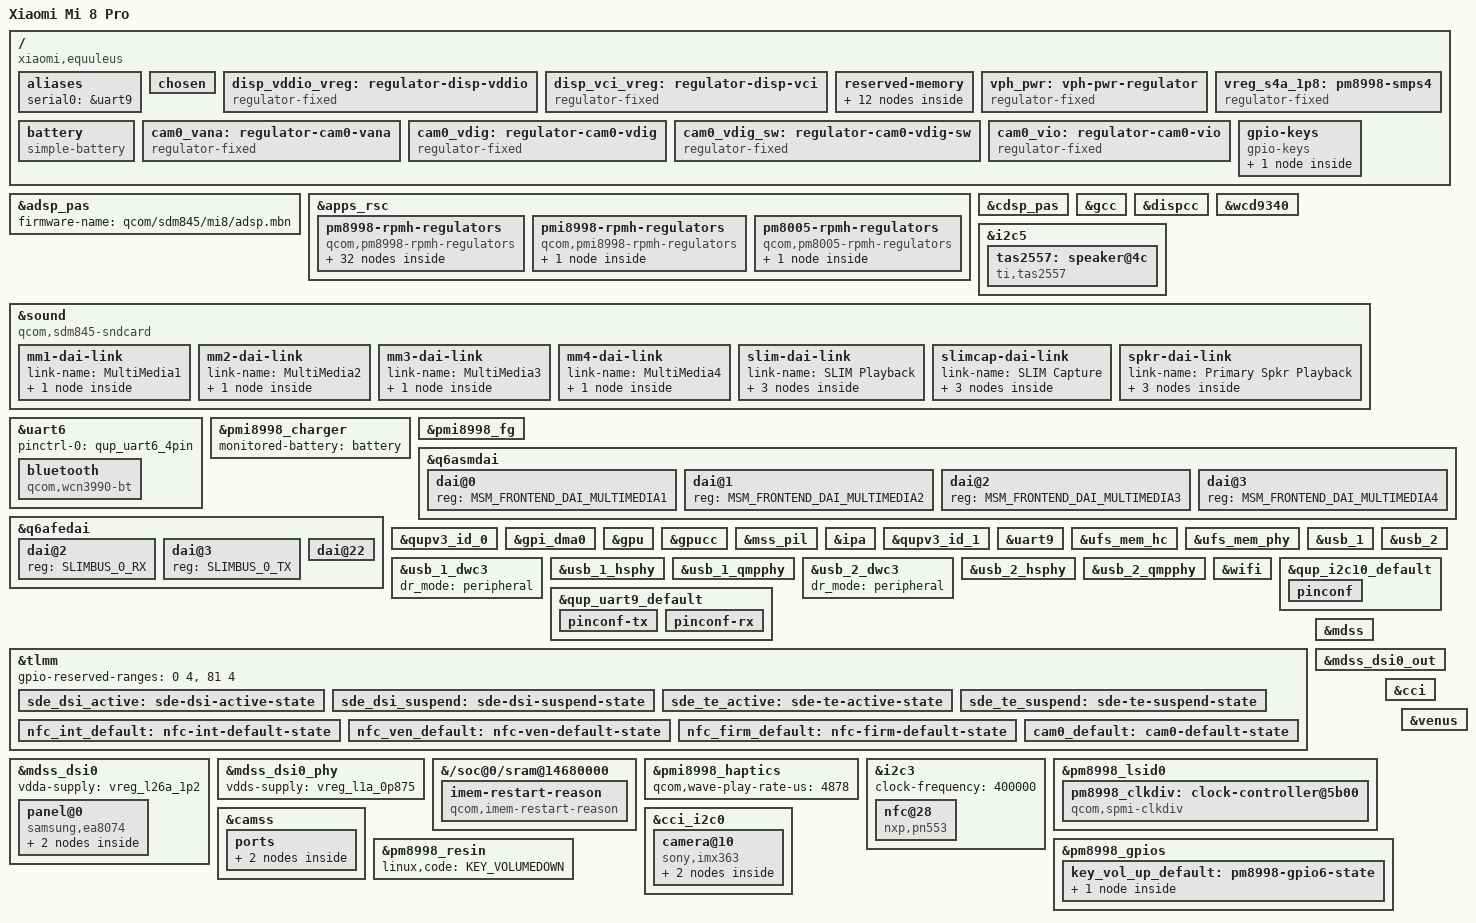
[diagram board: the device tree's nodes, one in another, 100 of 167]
// SPDX-License-Identifier: GPL-2.0
/*
 * SDM845 Xiaomi Mi 8 Pro (equuleus) device tree
 *
 * Copyright (c) 2021, The Linux Foundation. All rights reserved.
 */

/dts-v1/;

#include <dt-bindings/clock/qcom,camcc-sdm845.h>
#include <dt-bindings/gpio/gpio.h>
#include <dt-bindings/input/linux-event-codes.h>
#include <dt-bindings/pinctrl/qcom,pmic-gpio.h>
#include <dt-bindings/regulator/qcom,rpmh-regulator.h>
#include <dt-bindings/spmi/spmi.h>
#include <dt-bindings/sound/qcom,q6afe.h>
#include <dt-bindings/sound/qcom,q6asm.h>
#include <dt-bindings/sound/qcom,wcd934x.h>
#include "sdm845.dtsi"
/*
 * The WCD9340 codec on SLIMbus, shared by several sdm845 boards. It also
 * carries the interrupt pinctrl that the codec node references.
 */
#include "sdm845-wcd9340.dtsi"
/*
 * Brings in the PM8998 SPMI PMIC. Its PON block is what makes
 * "reboot bootloader" work: qcom-pon writes the reboot reason into the PMIC
 * scratch register and the bootloader reads it on the next boot to decide
 * between normal boot and fastboot. Without this include there is no pon@800
 * node at all, so qcom-pon binds to nothing and the reboot reason is lost.
 *
 * The file carries no regulators - those come from RPMh - so it does not
 * conflict with pm8998-rpmh-regulators.
 */
#include "pm8998.dtsi"
/*
 * The PMI8998 PMIC carries the charger and the fuel gauge. Board DTSes have to
 * include this themselves; nothing pulls it in automatically.
 */
#include "pmi8998.dtsi"

/*
 * Delete following upstream (sdm845.dtsi) reserved
 * memory mappings which are different in this device.
 */
/delete-node/ &tz_mem;
/delete-node/ &adsp_mem;
/delete-node/ &wlan_msa_mem;
/delete-node/ &mpss_region;
/delete-node/ &venus_mem;
/delete-node/ &cdsp_mem;
/delete-node/ &mba_region;
/delete-node/ &slpi_mem;
/delete-node/ &spss_mem;
/delete-node/ &rmtfs_mem;

/ {
	model = "Xiaomi Mi 8 Pro";
	compatible = "xiaomi,equuleus", "qcom,sdm845", "qcom,mtp";
	qcom,msm-id = <321 0x20001>;
	qcom,board-id = <79 0>;

	aliases {
		serial0 = &uart9;
	};

	chosen {
		#address-cells = <2>;
		#size-cells = <2>;
		ranges;


	};

	/*
	 * Panel rails. The downstream device tree switches both from tlmm gpios
	 * and expects them on at boot.
	 */
	disp_vddio_vreg: regulator-disp-vddio {
		compatible = "regulator-fixed";
		regulator-name = "disp_vddio";
		regulator-min-microvolt = <1800000>;
		regulator-max-microvolt = <1800000>;
		gpio = <&tlmm 23 GPIO_ACTIVE_HIGH>;
		enable-active-high;
		startup-delay-us = <4000>;
		regulator-boot-on;
	};

	disp_vci_vreg: regulator-disp-vci {
		compatible = "regulator-fixed";
		regulator-name = "disp_vci";
		regulator-min-microvolt = <3000000>;
		regulator-max-microvolt = <3000000>;
		gpio = <&tlmm 35 GPIO_ACTIVE_HIGH>;
		enable-active-high;
		startup-delay-us = <4000>;
		regulator-boot-on;
	};

	reserved-memory {

		/*
		 * pstore/ramoops: keep the last kernel messages in RAM across a
		 * reboot. Without this a panic leaves nothing behind - the console
		 * gadget only exists once the initramfs has started, so an early
		 * hang produces no output at all.
		 *
		 * Placed right after the framebuffer region (9d400000+02400000) and
		 * clear of everything sdm845.dtsi reserves below that.
		 */
		ramoops_region: ramoops@9f800000 {
			compatible = "ramoops";
			reg = <0x0 0x9f800000 0x0 0x100000>;
			record-size = <0x20000>;
			console-size = <0x40000>;
			ftrace-size = <0x0>;
			pmsg-size = <0x20000>;
		};

		/* hack: Framebuffer memory region. */
		framebuffer_region@9d400000 {
			reg = <0x0 0x9d400000 0x0 0x02400000>;
			no-map;
		};

		/* Reserved memory changes from downstream */
		adsp_mem: memory@8c500000 {
			reg = <0 0x8c500000 0 0x1e00000>;
			no-map;
		};

		wlan_msa_mem: memory@8e300000 {
			reg = <0 0x8e300000 0 0x100000>;
			no-map;
		};

		mpss_region: memory@8e400000 {
			reg = <0 0x8e400000 0 0x7800000>;
			no-map;
		};

		venus_mem: memory@95c00000 {
			reg = <0 0x95c00000 0 0x500000>;
			no-map;
		};

		cdsp_mem: memory@96100000 {
			reg = <0 0x96100000 0 0x800000>;
			no-map;
		};

		mba_region: memory@96900000 {
			reg = <0 0x96900000 0 0x200000>;
			no-map;
		};

		slpi_mem: memory@96b00000 {
			reg = <0 0x96b00000 0 0x1400000>;
			no-map;
		};

		spss_mem: memory@97f00000 {
			reg = <0 0x97f00000 0 0x100000>;
			no-map;
		};

		/*
		 * The rmtfs memory region in downstream is 'dynamically allocated'
		 * but given the same address every time. Hard code it as this address is
		 * where the modem firmware expects it to be.
		 */
		rmtfs_mem: memory@f7301000 {
			compatible = "qcom,rmtfs-mem";
			reg = <0 0xf7301000 0 0x200000>;
			no-map;

			qcom,client-id = <1>;
			qcom,vmid = <15>;
		};
		
		/*
		 * It seems like reserving the old rmtfs_mem region is also needed to prevent
		 * random crashes which are most likely modem related, more testing needed.
		 */
		removed_region: memory@88f00000 {
			no-map;
			reg = <0 0x88f00000 0 0x200000>;
		};
	};

	vph_pwr: vph-pwr-regulator {
		compatible = "regulator-fixed";
		regulator-name = "vph_pwr";
		regulator-min-microvolt = <3700000>;
		regulator-max-microvolt = <3700000>;
	};

	/*
	 * Apparently RPMh does not provide support for PM8998 S4 because it
	 * is always-on; model it as a fixed regulator.
	 */
	vreg_s4a_1p8: pm8998-smps4 {
		compatible = "regulator-fixed";
		regulator-name = "vreg_s4a_1p8";

		regulator-min-microvolt = <1800000>;
		regulator-max-microvolt = <1800000>;

		regulator-always-on;
		regulator-boot-on;

		vin-supply = <&vph_pwr>;
	};
};

&adsp_pas {
	status = "okay";
	firmware-name = "qcom/sdm845/mi8/adsp.mbn";
};

&apps_rsc {
	pm8998-rpmh-regulators {
		compatible = "qcom,pm8998-rpmh-regulators";
		qcom,pmic-id = "a";

		vdd-s1-supply = <&vph_pwr>;
		vdd-s2-supply = <&vph_pwr>;
		vdd-s3-supply = <&vph_pwr>;
		vdd-s4-supply = <&vph_pwr>;
		vdd-s5-supply = <&vph_pwr>;
		vdd-s6-supply = <&vph_pwr>;
		vdd-s7-supply = <&vph_pwr>;
		vdd-s8-supply = <&vph_pwr>;
		vdd-s9-supply = <&vph_pwr>;
		vdd-s10-supply = <&vph_pwr>;
		vdd-s11-supply = <&vph_pwr>;
		vdd-s12-supply = <&vph_pwr>;
		vdd-s13-supply = <&vph_pwr>;
		vdd-l1-l27-supply = <&vreg_s7a_1p025>;
		vdd-l2-l8-l17-supply = <&vreg_s3a_1p35>;
		vdd-l3-l11-supply = <&vreg_s7a_1p025>;
		vdd-l4-l5-supply = <&vreg_s7a_1p025>;
		vdd-l6-supply = <&vph_pwr>;
		vdd-l7-l12-l14-l15-supply = <&vreg_s5a_2p04>;
		vdd-l9-supply = <&vreg_bob>;
		vdd-l10-l23-l25-supply = <&vreg_bob>;
		vdd-l13-l19-l21-supply = <&vreg_bob>;
		vdd-l16-l28-supply = <&vreg_bob>;
		vdd-l18-l22-supply = <&vreg_bob>;
		vdd-l20-l24-supply = <&vreg_bob>;
		vdd-l26-supply = <&vreg_s3a_1p35>;
		vin-lvs-1-2-supply = <&vreg_s4a_1p8>;

		vreg_s2a_1p125: smps2 {
			regulator-min-microvolt = <1100000>;
			regulator-max-microvolt = <1100000>;
		};

		vreg_s3a_1p35: smps3 {
			regulator-min-microvolt = <1352000>;
			regulator-max-microvolt = <1352000>;
		};

		vreg_s5a_2p04: smps5 {
			regulator-min-microvolt = <1904000>;
			regulator-max-microvolt = <2040000>;
		};

		vreg_s7a_1p025: smps7 {
			regulator-min-microvolt = <900000>;
			regulator-max-microvolt = <1028000>;
		};

		vdd_qusb_hs0:
		vdda_hp_pcie_core:
		vdda_mipi_csi0_0p9:
		vdda_mipi_csi1_0p9:
		vdda_mipi_csi2_0p9:
		vdda_mipi_dsi0_pll:
		vdda_mipi_dsi1_pll:
		vdda_qlink_lv:
		vdda_qlink_lv_ck:
		vdda_qrefs_0p875:
		vdda_pcie_core:
		vdda_pll_cc_ebi01:
		vdda_pll_cc_ebi23:
		vdda_sp_sensor:
		vdda_ufs1_core:
		vdda_ufs2_core:
		vdda_usb1_ss_core:
		vdda_usb2_ss_core:
		vreg_l1a_0p875: ldo1 {
			regulator-min-microvolt = <880000>;
			regulator-max-microvolt = <880000>;
			regulator-initial-mode = <RPMH_REGULATOR_MODE_HPM>;
		};

		vddpx_10:
		vreg_l2a_1p2: ldo2 {
			regulator-min-microvolt = <1200000>;
			regulator-max-microvolt = <1200000>;
			regulator-initial-mode = <RPMH_REGULATOR_MODE_HPM>;
			regulator-always-on;
		};

		vreg_l3a_1p0: ldo3 {
			regulator-min-microvolt = <1000000>;
			regulator-max-microvolt = <1000000>;
			regulator-initial-mode = <RPMH_REGULATOR_MODE_HPM>;
		};

		vdd_wcss_cx:
		vdd_wcss_mx:
		vdda_wcss_pll:
		vreg_l5a_0p8: ldo5 {
			regulator-min-microvolt = <800000>;
			regulator-max-microvolt = <800000>;
			regulator-initial-mode = <RPMH_REGULATOR_MODE_HPM>;
		};

		vddpx_13:
		vreg_l6a_1p8: ldo6 {
			regulator-min-microvolt = <1856000>;
			regulator-max-microvolt = <1856000>;
			regulator-initial-mode = <RPMH_REGULATOR_MODE_HPM>;
		};

		vreg_l7a_1p8: ldo7 {
			regulator-min-microvolt = <1800000>;
			regulator-max-microvolt = <1800000>;
			regulator-initial-mode = <RPMH_REGULATOR_MODE_HPM>;
		};

		vreg_l8a_1p2: ldo8 {
			regulator-min-microvolt = <1200000>;
			regulator-max-microvolt = <1248000>;
			regulator-initial-mode = <RPMH_REGULATOR_MODE_HPM>;
		};

		vreg_l9a_1p8: ldo9 {
			regulator-min-microvolt = <1704000>;
			regulator-max-microvolt = <2928000>;
			regulator-initial-mode = <RPMH_REGULATOR_MODE_HPM>;
		};

		vreg_l10a_1p8: ldo10 {
			regulator-min-microvolt = <1704000>;
			regulator-max-microvolt = <2928000>;
			regulator-initial-mode = <RPMH_REGULATOR_MODE_HPM>;
		};

		vreg_l11a_1p0: ldo11 {
			regulator-min-microvolt = <1000000>;
			regulator-max-microvolt = <1048000>;
			regulator-initial-mode = <RPMH_REGULATOR_MODE_HPM>;
		};

		vdd_qfprom:
		vdd_qfprom_sp:
		vdda_apc1_cs_1p8:
		vdda_gfx_cs_1p8:
		vdda_qrefs_1p8:
		vdda_qusb_hs0_1p8:
		vddpx_11:
		vreg_l12a_1p8: ldo12 {
			regulator-min-microvolt = <1800000>;
			regulator-max-microvolt = <1800000>;
			regulator-initial-mode = <RPMH_REGULATOR_MODE_HPM>;
		};

		vddpx_2:
		vreg_l13a_2p95: ldo13 {
			regulator-min-microvolt = <1800000>;
			regulator-max-microvolt = <2960000>;
			regulator-initial-mode = <RPMH_REGULATOR_MODE_HPM>;
		};

		vreg_l14a_1p88: ldo14 {
			regulator-min-microvolt = <1800000>;
			regulator-max-microvolt = <1800000>;
			regulator-initial-mode = <RPMH_REGULATOR_MODE_HPM>;
		};

		vreg_l15a_1p8: ldo15 {
			regulator-min-microvolt = <1800000>;
			regulator-max-microvolt = <1800000>;
			regulator-initial-mode = <RPMH_REGULATOR_MODE_HPM>;
		};

		vreg_l16a_2p7: ldo16 {
			regulator-min-microvolt = <2704000>;
			regulator-max-microvolt = <2704000>;
			regulator-initial-mode = <RPMH_REGULATOR_MODE_HPM>;
		};

		vreg_l17a_1p3: ldo17 {
			regulator-min-microvolt = <1304000>;
			regulator-max-microvolt = <1304000>;
			regulator-initial-mode = <RPMH_REGULATOR_MODE_HPM>;
		};

		vreg_l18a_2p7: ldo18 {
			regulator-min-microvolt = <2704000>;
			regulator-max-microvolt = <2960000>;
			regulator-initial-mode = <RPMH_REGULATOR_MODE_HPM>;
		};

		vreg_l19a_3p0: ldo19 {
			regulator-min-microvolt = <2856000>;
			regulator-max-microvolt = <3104000>;
			regulator-initial-mode = <RPMH_REGULATOR_MODE_HPM>;
		};

		vreg_l20a_2p95: ldo20 {
			regulator-min-microvolt = <2704000>;
			regulator-max-microvolt = <2960000>;
			regulator-initial-mode = <RPMH_REGULATOR_MODE_HPM>;
		};

		vreg_l21a_2p95: ldo21 {
			regulator-min-microvolt = <2704000>;
			regulator-max-microvolt = <2960000>;
			regulator-initial-mode = <RPMH_REGULATOR_MODE_HPM>;
		};

		vreg_l22a_2p85: ldo22 {
			regulator-min-microvolt = <2864000>;
			regulator-max-microvolt = <3312000>;
			regulator-initial-mode = <RPMH_REGULATOR_MODE_HPM>;
		};

		vreg_l23a_3p3: ldo23 {
			regulator-min-microvolt = <3000000>;
			regulator-max-microvolt = <3312000>;
			regulator-initial-mode = <RPMH_REGULATOR_MODE_HPM>;
		};

		vdda_qusb_hs0_3p1:
		vreg_l24a_3p075: ldo24 {
			regulator-min-microvolt = <3088000>;
			regulator-max-microvolt = <3088000>;
			regulator-initial-mode = <RPMH_REGULATOR_MODE_HPM>;
		};

		vreg_l25a_3p3: ldo25 {
			regulator-min-microvolt = <3300000>;
			regulator-max-microvolt = <3312000>;
			regulator-initial-mode = <RPMH_REGULATOR_MODE_HPM>;
		};

		vdda_hp_pcie_1p2:
		vdda_hv_ebi0:
		vdda_hv_ebi1:
		vdda_hv_ebi2:
		vdda_hv_ebi3:
		vdda_mipi_csi_1p25:
		vdda_mipi_dsi0_1p2:
		vdda_mipi_dsi1_1p2:
		vdda_pcie_1p2:
		vdda_ufs1_1p2:
		vdda_ufs2_1p2:
		vdda_usb1_ss_1p2:
		vdda_usb2_ss_1p2:
		vreg_l26a_1p2: ldo26 {
			regulator-min-microvolt = <1200000>;
			regulator-max-microvolt = <1200000>;
			regulator-initial-mode = <RPMH_REGULATOR_MODE_HPM>;
		};

		vreg_l28a_3p0: ldo28 {
			regulator-min-microvolt = <2856000>;
			regulator-max-microvolt = <3008000>;
			regulator-initial-mode = <RPMH_REGULATOR_MODE_HPM>;
		};

		vreg_lvs1a_1p8: lvs1 {
			regulator-min-microvolt = <1800000>;
			regulator-max-microvolt = <1800000>;
		};

		vreg_lvs2a_1p8: lvs2 {
			regulator-min-microvolt = <1800000>;
			regulator-max-microvolt = <1800000>;
		};
	};

	pmi8998-rpmh-regulators {
		compatible = "qcom,pmi8998-rpmh-regulators";
		qcom,pmic-id = "b";

		vdd-bob-supply = <&vph_pwr>;

		vreg_bob: bob {
			regulator-min-microvolt = <3312000>;
			regulator-max-microvolt = <3600000>;
			regulator-initial-mode = <RPMH_REGULATOR_MODE_AUTO>;
			regulator-allow-bypass;
		};
	};

	pm8005-rpmh-regulators {
		compatible = "qcom,pm8005-rpmh-regulators";
		qcom,pmic-id = "c";

		vdd-s1-supply = <&vph_pwr>;
		vdd-s2-supply = <&vph_pwr>;
		vdd-s3-supply = <&vph_pwr>;
		vdd-s4-supply = <&vph_pwr>;

		vreg_s3c_0p6: smps3 {
			regulator-min-microvolt = <600000>;
			regulator-max-microvolt = <600000>;
		};
	};
};

&cdsp_pas {
	status = "okay";
};

&gcc {
	protected-clocks = <GCC_QSPI_CORE_CLK>,
			   <GCC_QSPI_CORE_CLK_SRC>,
			   <GCC_QSPI_CNOC_PERIPH_AHB_CLK>,
			   <GCC_LPASS_Q6_AXI_CLK>,
			   <GCC_LPASS_SWAY_CLK>;
};

&dispcc {
	status = "okay";
};


/* ---------------------------------------------------------------------------
 * Audio
 * ------------------------------------------------------------------------- */

&wcd9340 {
	reset-gpios = <&tlmm 64 GPIO_ACTIVE_HIGH>;
	vdd-buck-supply = <&vreg_s4a_1p8>;
	vdd-buck-sido-supply = <&vreg_s4a_1p8>;
	vdd-tx-supply = <&vreg_s4a_1p8>;
	vdd-rx-supply = <&vreg_s4a_1p8>;
	vdd-io-supply = <&vreg_s4a_1p8>;

	qcom,micbias1-microvolt = <2700000>;
	qcom,micbias2-microvolt = <1800000>;
	qcom,micbias3-microvolt = <2700000>;
	qcom,micbias4-microvolt = <2700000>;
};

/*
 * Speaker amplifier. Address, reset GPIO and IRQ GPIO come from the downstream
 * device tree for this board.
 */
&i2c5 {
	status = "okay";

	tas2557: speaker@4c {
		compatible = "ti,tas2557";
		reg = <0x4c>;
		#sound-dai-cells = <1>;
		ti,cdc-reset-gpio = <&tlmm 76 GPIO_ACTIVE_HIGH>;
		ti,irq-gpio = <&tlmm 30 GPIO_ACTIVE_HIGH>;
		ti,i2s-bits = <16>;
		ti,bypass-tmax;
	};
};

&sound {
	compatible = "qcom,sdm845-sndcard";
	model = "Xiaomi Mi 8 Pro";
	status = "okay";

	pinctrl-0 = <&quat_mi2s_active &quat_mi2s_sd0_active>;
	pinctrl-names = "default";

	audio-routing =
		"RX_BIAS", "MCLK",
		"AMIC1", "MIC BIAS1",
		"AMIC2", "MIC BIAS2",
		"AMIC3", "MIC BIAS3";

	mm1-dai-link {
		link-name = "MultiMedia1";
		cpu {
			sound-dai = <&q6asmdai MSM_FRONTEND_DAI_MULTIMEDIA1>;
		};
	};

	mm2-dai-link {
		link-name = "MultiMedia2";
		cpu {
			sound-dai = <&q6asmdai MSM_FRONTEND_DAI_MULTIMEDIA2>;
		};
	};

	mm3-dai-link {
		link-name = "MultiMedia3";
		cpu {
			sound-dai = <&q6asmdai MSM_FRONTEND_DAI_MULTIMEDIA3>;
		};
	};

	mm4-dai-link {
		link-name = "MultiMedia4";
		cpu {
			sound-dai = <&q6asmdai MSM_FRONTEND_DAI_MULTIMEDIA4>;
		};
	};

	/* Earpiece and wired headset hang off the codec. */
	slim-dai-link {
		link-name = "SLIM Playback";
		cpu {
			sound-dai = <&q6afedai SLIMBUS_0_RX>;
		};

		platform {
			sound-dai = <&q6routing>;
		};

		codec {
			sound-dai = <&wcd9340 AIF1_PB>;
		};
	};

	slimcap-dai-link {
		link-name = "SLIM Capture";
		cpu {
			sound-dai = <&q6afedai SLIMBUS_0_TX>;
		};

		platform {
			sound-dai = <&q6routing>;
		};

		codec {
			sound-dai = <&wcd9340 AIF1_CAP>;
		};
	};

	/* Loudspeaker goes through the amplifier over QUATERNARY MI2S. */
	spkr-dai-link {
		link-name = "Primary Spkr Playback";

		cpu {
			sound-dai = <&q6afedai QUATERNARY_MI2S_RX>;
		};

		platform {
			sound-dai = <&q6routing>;
		};

		codec {
			sound-dai = <&tas2557 0>;
		};
	};
};

/*
 * Bluetooth is on QUP SE6 (uart6 at 0x898000). Downstream enables
 * qupv3_se6_4uart for it; our console is uart9, a different instance.
 */
&uart6 {
	/*
	 * The default group in sdm845.dtsi is TX/RX only. The WCN3990 needs RTS and CTS
	 * as well: hci_qca calls hci_uart_set_flow_control(hu, true) before switching
	 * the baud rate, so that the controller can hold the host off while it
	 * reprograms itself. With the pins not muxed to the UART that is a no-op, the
	 * acknowledgement is lost, and the switch fails:
	 *
	 *   Bluetooth: hci0: Frame reassembly failed (-84)
	 *   Bluetooth: hci0: Failed to change controller baudrate
	 *
	 * beryllium and the working Mi 8 device tree both override this the same way.
	 */
	pinctrl-0 = <&qup_uart6_4pin>;
	status = "okay";

	bluetooth: bluetooth {
		compatible = "qcom,wcn3990-bt";

		vddio-supply = <&vreg_s3a_1p35>;
		vddxo-supply = <&vreg_s5a_2p04>;
		vddrf-supply = <&vreg_l17a_1p3>;
		vddch0-supply = <&vreg_l25a_3p3>;

		max-speed = <3200000>;
	};
};

/* ---------------------------------------------------------------------------
 * Battery
 * ------------------------------------------------------------------------- */

/ {
	battery: battery {
		compatible = "simple-battery";

		/* equuleus ships a 3000 mAh pack; the downstream tree lists both
		 * the coslight and the atl variant at that capacity. */
		charge-full-design-microamp-hours = <3000000>;
		voltage-min-design-microvolt = <3400000>;
		voltage-max-design-microvolt = <4400000>;
	};
};

&pmi8998_charger {
	status = "okay";
	monitored-battery = <&battery>;
};

&pmi8998_fg {
	status = "okay";
	monitored-battery = <&battery>;
	power-supplies = <&pmi8998_charger>;
};

/*
 * Front-end DAIs for playback. The shared sdm845.dtsi only defines the
 * containers; each board declares the ones it uses.
 */
&q6asmdai {
	dai@0 {
		reg = <MSM_FRONTEND_DAI_MULTIMEDIA1>;
	};

	dai@1 {
		reg = <MSM_FRONTEND_DAI_MULTIMEDIA2>;
	};

	dai@2 {
		reg = <MSM_FRONTEND_DAI_MULTIMEDIA3>;
	};

	dai@3 {
		reg = <MSM_FRONTEND_DAI_MULTIMEDIA4>;
	};
};

/*
 * Back-end ports. SLIMBUS_0 carries the WCD9340 (earpiece, headset, mics);
 * QUATERNARY MI2S feeds the TAS2557 speaker amplifier.
 */
&q6afedai {
	dai@2 {
		reg = <SLIMBUS_0_RX>;
	};

	dai@3 {
		reg = <SLIMBUS_0_TX>;
	};

	dai@22 {
		reg = <QUATERNARY_MI2S_RX>;
		qcom,sd-lines = <0>;
	};
};

/*
 * QUP wrapper 0 carries uart6, which is where the WCN3990 Bluetooth controller
 * sits. Without this the serial@898000 platform device is never created, so
 * there is no ttyHS and no HCI device.
 */
&qupv3_id_0 {
	status = "okay";
};

/*
 * i2c5 drives the TAS2557 speaker amplifier and its dmas property references
 * gpi_dma0, which sdm845.dtsi leaves disabled. Without this the I2C controller
 * cannot acquire its DMA channels and the amplifier never appears.
 */
&gpi_dma0 {
	status = "okay";
};

/*
 * Adreno 630.
 *
 * The zap shader is signed by Xiaomi and is not redistributable: it has to be
 * pulled out of the vendor image of a stock fastboot ROM and installed as
 * qcom/a630_zap.mbn. msm is built in and loads the firmware before the root
 * filesystem is mounted, so the file has to be reachable from the initramfs.
 */
&gpu {
	status = "okay";
};

&gpucc {
	status = "okay";
};

/* Modem/wifi*/
&mss_pil {
	status = "okay";
	firmware-name = "qcom/sdm845/mi8/mba.mbn", "qcom/sdm845/mi8/modem.mbn";
};

/*
 * IPA (IP Accelerator) is the pipe the modem uses for its data traffic. The
 * firmware is loaded by the AP and handed to Trust Zone for authentication,
 * which is the "self" loader mode the other Xiaomi boards already in mainline
 * use (sdm845-xiaomi-perseus.dts, sdm845-xiaomi-polaris.dts). The reserved
 * regions ipa_fw_mem and ipa_gsi_mem come from sdm845.dtsi, so only the
 * firmware path differs per board.
 *
 * The stock vendor image ships the firmware as ipa_fws.mdt plus .b00..b04
 * segments; the driver requests the .mdt and qcom_mdt_load() resolves the
 * segments by basename, so both must be present at that path.
 */
&ipa {
	memory-region = <&ipa_fw_mem>;
	firmware-name = "qcom/sdm845/mi8/ipa_fws.mdt";
	qcom,gsi-loader = "self";

	status = "okay";
};

&qupv3_id_1 {
	status = "okay";
};

&uart9 {
	status = "okay";
};

&ufs_mem_hc {
	status = "okay";

	reset-gpios = <&tlmm 150 GPIO_ACTIVE_LOW>;

	vcc-supply = <&vreg_l20a_2p95>;
	vcc-max-microamp = <600000>;
};

&ufs_mem_phy {
	status = "okay";

	vdda-phy-supply = <&vdda_ufs1_core>;
	vdda-pll-supply = <&vdda_ufs1_1p2>;
};

&usb_1 {
	status = "okay";
};

&usb_1_dwc3 {
	/* Until we have Type C hooked up we'll force this as peripheral. */
	dr_mode = "peripheral";
};

&usb_1_hsphy {
	status = "okay";

	vdd-supply = <&vdda_usb1_ss_core>;
	vdda-pll-supply = <&vdda_qusb_hs0_1p8>;
	vdda-phy-dpdm-supply = <&vdda_qusb_hs0_3p1>;

	qcom,imp-res-offset-value = <8>;
	qcom,hstx-trim-value = <QUSB2_V2_HSTX_TRIM_21_6_MA>;
	qcom,preemphasis-level = <QUSB2_V2_PREEMPHASIS_5_PERCENT>;
	qcom,preemphasis-width = <QUSB2_V2_PREEMPHASIS_WIDTH_HALF_BIT>;
};

&usb_1_qmpphy {
	status = "okay";

	vdda-phy-supply = <&vdda_usb1_ss_1p2>;
	vdda-pll-supply = <&vdda_usb1_ss_core>;
};

&usb_2 {
	status = "okay";
};

&usb_2_dwc3 {
	/*
	 * Though the USB block on SDM845 can support host, there's no vbus
	 * signal for this port on MTP.  Thus (unless you have a non-compliant
	 * hub that works without vbus) the only sensible thing is to force
	 * peripheral mode.
	 */
	dr_mode = "peripheral";
};

&usb_2_hsphy {
	status = "okay";

	vdd-supply = <&vdda_usb2_ss_core>;
	vdda-pll-supply = <&vdda_qusb_hs0_1p8>;
	vdda-phy-dpdm-supply = <&vdda_qusb_hs0_3p1>;

	qcom,imp-res-offset-value = <8>;
	qcom,hstx-trim-value = <QUSB2_V2_HSTX_TRIM_22_8_MA>;
};

&usb_2_qmpphy {
	status = "okay";

	vdda-phy-supply = <&vdda_usb2_ss_1p2>;
	vdda-pll-supply = <&vdda_usb2_ss_core>;
};

&wifi {
	status = "okay";

	vdd-0.8-cx-mx-supply = <&vreg_l5a_0p8>;
	vdd-1.8-xo-supply = <&vreg_l7a_1p8>;
	vdd-1.3-rfa-supply = <&vreg_l17a_1p3>;
	vdd-3.3-ch0-supply = <&vreg_l25a_3p3>;
	/* Second 3.3V RF rail. beryllium and perseus both describe it; without it
	 * the driver falls back to a dummy regulator and the ch1 front end never
	 * powers up, which is enough to make the QMI handshake fail. */
	vdd-3.3-ch1-supply = <&vreg_l23a_3p3>;

	/*
	 * WCN3990 on Xiaomi boards needs the host capability handshake skipped,
	 * same as beryllium and perseus. Without it the firmware load stalls.
	 */
	qcom,snoc-host-cap-skip-quirk;
};

/* PINCTRL - additions to nodes defined in sdm845.dtsi */

&qup_i2c10_default {
	pinconf {
		pins = "gpio55", "gpio56";
		drive-strength = <2>;
		bias-disable;
	};
};

&qup_uart9_default {
	pinconf-tx {
		pins = "gpio4";
		drive-strength = <2>;
		bias-disable;
	};

	pinconf-rx {
		pins = "gpio5";
		drive-strength = <2>;
		bias-pull-up;
	};
};

&tlmm {
	gpio-reserved-ranges = <0 4>, <81 4>;
};

/*
 * Display pipeline.
 *
 * This is what keeps the SoC alive: it takes MDSS away from the bootloader
 * splash and gives the DPU a driver that votes for the memory path. See the
 * comment at the top of this patch for the full failure chain.
 */
&mdss {
	status = "okay";
};

&mdss_dsi0 {
	vdda-supply = <&vreg_l26a_1p2>;
	status = "okay";

	panel@0 {
		compatible = "samsung,ea8074";
		reg = <0>;

		reset-gpios = <&tlmm 6 GPIO_ACTIVE_LOW>;
		vddio-supply = <&disp_vddio_vreg>;
		vci-supply = <&disp_vci_vreg>;

		pinctrl-0 = <&sde_dsi_active &sde_te_active>;
		pinctrl-1 = <&sde_dsi_suspend &sde_te_suspend>;
		pinctrl-names = "default", "sleep";

		port {
			panel_in: endpoint {
				remote-endpoint = <&mdss_dsi0_out>;
			};
		};
	};
};

&mdss_dsi0_out {
	data-lanes = <0 1 2 3>;
	remote-endpoint = <&panel_in>;
};

&mdss_dsi0_phy {
	vdds-supply = <&vreg_l1a_0p875>;
	status = "okay";
};

&tlmm {
	sde_dsi_active: sde-dsi-active-state {
		pins = "gpio6";
		function = "gpio";
		drive-strength = <8>;
		bias-disable;
	};

	sde_dsi_suspend: sde-dsi-suspend-state {
		pins = "gpio6";
		function = "gpio";
		drive-strength = <2>;
		bias-pull-down;
	};

	sde_te_active: sde-te-active-state {
		pins = "gpio10";
		function = "mdp_vsync";
		drive-strength = <2>;
		bias-pull-down;
	};

	sde_te_suspend: sde-te-suspend-state {
		pins = "gpio10";
		function = "mdp_vsync";
		drive-strength = <2>;
		bias-pull-down;
	};
};

/*
 * "reboot bootloader" is an ordinary reboot without this: the ABL reads a magic
 * in IMEM rather than the PMIC register mainline's qcom-pon writes. The vendor
 * kernel puts 0x77665500 at IMEM + 0x65c for fastboot, 0x77665502 for recovery.
 */
/*
 * "reboot bootloader" is an ordinary reboot without this: the ABL reads a magic
 * in IMEM rather than the PMIC register mainline's qcom-pon writes. The vendor
 * kernel puts 0x77665500 at IMEM + 0x65c for fastboot, 0x77665502 for recovery.
 *
 * The parent sram@14680000 has no label upstream, so this is added as a child by
 * path rather than through a phandle reference.
 */
&{/soc@0/sram@14680000} {
	imem-restart-reason {
		compatible = "qcom,imem-restart-reason";
	};
};
/*
 * Haptic motor. PMI8998 drives it; the sibling Xiaomi boards (dipper, perseus)
 * only override the wave play rate, so the defaults in pmi8998.dtsi (sine wave,
 * buffer play mode, brake pattern) are what the hardware expects.
 */
&pmi8998_haptics {
	qcom,wave-play-rate-us = <4878>;

	status = "okay";
};
/*
 * NFC: NXP PN553 on i2c3. The vendor tree describes it as nq@28 on i2c@88c000,
 * with VEN on GPIO 128, FIRM on GPIO 88 and the interrupt on GPIO 63.
 *
 * Only the transport is described: the NCI protocol runs in userspace (neard /
 * libnfc), which is how this driver is meant to be used. The RF clock comes from
 * the PMIC (BBCLK3 in the vendor tree) and mainline does not model it, so the
 * controller depends on the bootloader leaving that clock running.
 */
&i2c3 {
	status = "okay";
	clock-frequency = <400000>;

	nfc@28 {
		compatible = "nxp,pn553", "nxp,nxp-nci-i2c";
		reg = <0x28>;

		interrupt-parent = <&tlmm>;
		interrupts = <63 IRQ_TYPE_EDGE_RISING>;

		enable-gpios = <&tlmm 128 GPIO_ACTIVE_HIGH>;
		firmware-gpios = <&tlmm 88 GPIO_ACTIVE_HIGH>;

		pinctrl-names = "default";
		pinctrl-0 = <&nfc_int_default &nfc_ven_default &nfc_firm_default>;
	};
};

&tlmm {
	nfc_int_default: nfc-int-default-state {
		pins = "gpio63";
		function = "gpio";

		drive-strength = <2>;
		bias-pull-up;
	};

	nfc_ven_default: nfc-ven-default-state {
		pins = "gpio128";
		function = "gpio";

		drive-strength = <2>;
		bias-disable;
	};

	nfc_firm_default: nfc-firm-default-state {
		pins = "gpio88";
		function = "gpio";

		drive-strength = <2>;
		bias-disable;
	};
};
/*
 * PM8998 clock dividers. BBCLK3 (divider 3, 0x5d00) is the NFC controller's
 * reference clock in the vendor tree ("qcom,clk-src = BBCLK3"). Mainline has no
 * node for it, and the driver enable is what actually starts the output, so the
 * driver marks the dividers critical for now (see clk-spmi-pmic-div.c).
 */
&pm8998_lsid0 {
	pm8998_clkdiv: clock-controller@5b00 {
		compatible = "qcom,spmi-clkdiv";
		reg = <0x5b00>;
		#clock-cells = <1>;
		clocks = <&rpmhcc RPMH_CXO_CLK>;
		clock-names = "xo";
		qcom,num-clkdivs = <3>;
		clock-output-names = "div_clk1", "div_clk2", "div_clk3";
	};
};
/*
 * Rear main camera: Sony IMX363 on CCI master 0 / CSIPHY 0.
 *
 * Wiring comes from the vendor device tree for the Equuleus MP v2.1 variant:
 * reset on GPIO 80 (active low), MCLK0 from camcc at 24 MHz, VANA 2.85 V through
 * a switch on GPIO 102 (fed from PM8998 L22), VDIG 1.35 V switched by GPIO 99
 * and VIO 1.8 V switched by GPIO 75. The sensor answers at I2C address 0x10 on
 * the first CCI bus.
 */
/ {
	cam0_vana: regulator-cam0-vana {
		compatible = "regulator-fixed";
		regulator-name = "cam0_vana";
		regulator-min-microvolt = <2850000>;
		regulator-max-microvolt = <2850000>;
		gpio = <&tlmm 102 GPIO_ACTIVE_HIGH>;
		enable-active-high;
		vin-supply = <&vreg_l22a_2p85>;
		startup-delay-us = <1000>;
	
	};

	cam0_vdig: regulator-cam0-vdig {
		compatible = "regulator-fixed";
		regulator-name = "cam0_vdig";
		regulator-min-microvolt = <1350000>;
		regulator-max-microvolt = <1350000>;
		gpio = <&tlmm 99 GPIO_ACTIVE_HIGH>;
		enable-active-high;
		startup-delay-us = <1000>;
	
	};

	/*
	 * The vendor tree switches VDIG twice: the 1.35 V rail is gated by
	 * TLMM 99 and the supply that actually reaches the sensor is gated by
	 * PM8998 GPIO 11 ("CAM_VDIG0" in the camera power table). Without the
	 * second stage the sensor stays unpowered and every read times out.
	 */
	cam0_vdig_sw: regulator-cam0-vdig-sw {
		compatible = "regulator-fixed";
		regulator-name = "cam0_vdig_sw";
		regulator-min-microvolt = <1350000>;
		regulator-max-microvolt = <1350000>;
		gpio = <&pm8998_gpios 11 GPIO_ACTIVE_HIGH>;
		enable-active-high;
		vin-supply = <&cam0_vdig>;
	
	};

	cam0_vio: regulator-cam0-vio {
		compatible = "regulator-fixed";
		regulator-name = "cam0_vio";
		regulator-min-microvolt = <1800000>;
		regulator-max-microvolt = <1800000>;
		gpio = <&tlmm 75 GPIO_ACTIVE_HIGH>;
		enable-active-high;
		startup-delay-us = <1000>;
	
	};
};

&tlmm {
	cam0_default: cam0-default-state {
		pins = "gpio80";
		function = "gpio";

		drive-strength = <2>;
		bias-disable;
	};
};

&cci {
	status = "okay";
};

&camss {
	vdda-phy-supply = <&vreg_l1a_0p875>;
	vdda-pll-supply = <&vreg_l26a_1p2>;

	status = "okay";

	ports {
		#address-cells = <1>;
		#size-cells = <0>;

		port@0 {
			reg = <0>;

			csiphy0_ep: endpoint {
				clock-lanes = <7>;
				data-lanes = <0 1 2 3>;

				remote-endpoint = <&imx363_ep>;
			};
		};
	};
};

&cci_i2c0 {
	status = "okay";

	camera@10 {
		compatible = "sony,imx363";
		reg = <0x10>;

		reset-gpios = <&tlmm 80 GPIO_ACTIVE_LOW>;

		pinctrl-names = "default";
		pinctrl-0 = <&cam0_default &cam_mclk0_default>;

		clocks = <&clock_camcc CAM_CC_MCLK0_CLK>;
		clock-names = "xvclk";
		clock-frequency = <24000000>;

		vana-supply = <&cam0_vana>;
		vdig-supply = <&cam0_vdig_sw>;
		vif-supply = <&cam0_vio>;

		orientation = <1>;
		rotation = <270>;

		status = "okay";

		port {
			imx363_ep: endpoint {
				clock-lanes = <1>;
				data-lanes = <1 2 3 4>;
				link-frequencies = /bits/ 64 <636000000>;

				remote-endpoint = <&csiphy0_ep>;
			};
		};
	};
};
/*
 * Volume keys, for use as custom hotkeys.
 *
 * The power key is left alone: pm8998_pwrkey already reports KEY_POWER and
 * systemd-logind keeps its default poweroff action.
 *
 * Volume up hangs off PM8998 GPIO 6 (active low) - the vendor tree labels it
 * "volume_up" and OnePlus 6, which uses the same PMIC, wires it to the same pin.
 * Volume down is not a GPIO at all: it is the PMIC's "resin" input, which the
 * vendor PON node reports as pon_2 with KEY_VOLUMEDOWN. Mainline ships that node
 * disabled, so it only needs enabling plus a keycode.
 */
&pm8998_gpios {
	key_vol_up_default: pm8998-gpio6-state {
		pinconf {
			pins = "gpio6";
			function = "normal";
			input-enable;
			bias-pull-up;
			qcom,drive-strength = <PMIC_GPIO_STRENGTH_NO>;
		};
	};
};

/ {
	gpio-keys {
		compatible = "gpio-keys";
		label = "Volume keys";
		autorepeat;

		pinctrl-names = "default";
		pinctrl-0 = <&key_vol_up_default>;

		key-vol-up {
			label = "Volume up";
			linux,code = <KEY_VOLUMEUP>;
			gpios = <&pm8998_gpios 6 GPIO_ACTIVE_LOW>;
			debounce-interval = <15>;
		};
	};
};

&pm8998_resin {
	status = "okay";
	linux,code = <KEY_VOLUMEDOWN>;
};
/*
 * Hardware video codec (Venus).
 *
 * The reserved region the driver needs is already declared above (venus_mem at
 * 0x95c00000, 5 MiB, matching the vendor layout), and videocc comes up with the
 * other clock controllers, so enabling the node is all that is needed. The
 * firmware is the generic qcom/sdm845/venus.mbn from linux-firmware; unlike the
 * OnePlus 6 this board does not appear to need a per-vendor copy.
 */
&venus {
	status = "okay";
};
